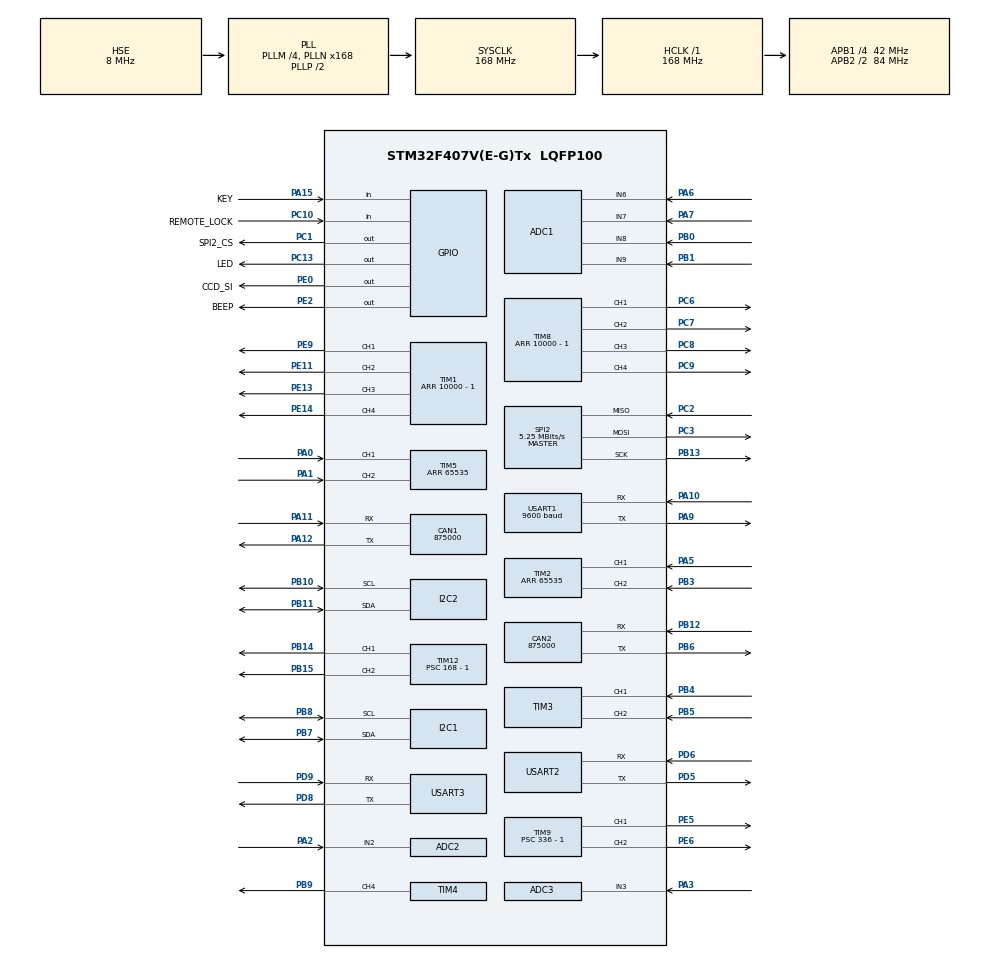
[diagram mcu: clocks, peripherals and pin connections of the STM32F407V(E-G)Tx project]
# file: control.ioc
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ADC1.Channel-1\#ChannelRegularConversion=ADC_CHANNEL_6
ADC1.NbrOfConversionFlag=1
ADC1.Rank-1\#ChannelRegularConversion=1
ADC1.SamplingTime-1\#ChannelRegularConversion=ADC_SAMPLETIME_3CYCLES
ADC1.master=1
ADC2.Channel-1\#ChannelRegularConversion=ADC_CHANNEL_2
ADC2.NbrOfConversionFlag=1
ADC2.Rank-1\#ChannelRegularConversion=1
ADC2.SamplingTime-1\#ChannelRegularConversion=ADC_SAMPLETIME_480CYCLES
ADC3.Channel-3\#ChannelRegularConversion=ADC_CHANNEL_3
ADC3.ExternalTrigConv=ADC_EXTERNALTRIGCONV_T4_CC4
ADC3.NbrOfConversionFlag=1
ADC3.Rank-3\#ChannelRegularConversion=1
ADC3.SamplingTime-3\#ChannelRegularConversion=ADC_SAMPLETIME_3CYCLES
CAN1.CalculateBaudRate=875000
CAN1.CalculateTimeBit=1142
CAN1.CalculateTimeQuantum=380.95238095238096
CAN2.CalculateBaudRate=875000
CAN2.CalculateTimeBit=1142
CAN2.CalculateTimeQuantum=380.95238095238096
Dma.ADC3.0.Direction=DMA_PERIPH_TO_MEMORY
Dma.ADC3.0.FIFOMode=DMA_FIFOMODE_DISABLE
Dma.ADC3.0.Instance=DMA2_Stream0
Dma.ADC3.0.MemDataAlignment=DMA_MDATAALIGN_HALFWORD
Dma.ADC3.0.MemInc=DMA_MINC_ENABLE
Dma.ADC3.0.Mode=DMA_NORMAL
Dma.ADC3.0.PeriphDataAlignment=DMA_PDATAALIGN_HALFWORD
Dma.ADC3.0.PeriphInc=DMA_PINC_DISABLE
Dma.ADC3.0.Priority=DMA_PRIORITY_LOW
Dma.Request0=ADC3
Mcu.Family=STM32F4
Mcu.Name=STM32F407V(E-G)Tx
Mcu.Package=LQFP100
NVIC.DMA2_Stream0_IRQn=true\:0\:0\:true\:false\:true\:false\:true\:true
NVIC.PriorityGroup=NVIC_PRIORITYGROUP_4
NVIC.TIM2_IRQn=true\:0\:0\:false\:false\:true\:true\:true\:true
NVIC.TIM3_IRQn=true\:0\:0\:false\:false\:true\:true\:true\:true
NVIC.TIM4_IRQn=true\:0\:0\:false\:false\:true\:true\:true\:true
NVIC.TIM5_IRQn=true\:0\:0\:false\:false\:true\:true\:true\:true
NVIC.USART1_IRQn=true\:14\:0\:true\:false\:true\:true\:true\:true
PA0-WKUP.GPIO_PuPd=GPIO_PULLUP
PA0-WKUP.Signal=S_TIM5_CH1
PA1.GPIO_PuPd=GPIO_PULLUP
PA1.Signal=S_TIM5_CH2
PA10.Mode=Asynchronous
PA10.Signal=USART1_RX
PA11.Mode=CAN_Activate
PA11.Signal=CAN1_RX
PA12.Mode=CAN_Activate
PA12.Signal=CAN1_TX
PA13.Mode=Serial_Wire
PA13.Signal=SYS_JTMS-SWDIO
PA14.Mode=Serial_Wire
PA14.Signal=SYS_JTCK-SWCLK
PA15.GPIO_Label=KEY
PA15.GPIO_PuPd=GPIO_PULLUP
PA15.Signal=GPIO_Input
PA2.Signal=ADCx_IN2
PA3.Signal=ADCx_IN3
PA5.GPIO_PuPd=GPIO_PULLUP
PA5.Signal=S_TIM2_CH1_ETR
PA6.Signal=ADCx_IN6
PA7.Signal=ADCx_IN7
PA9.Mode=Asynchronous
PA9.Signal=USART1_TX
PB0.Signal=ADCx_IN8
PB1.Signal=ADCx_IN9
PB10.Mode=I2C
PB10.Signal=I2C2_SCL
PB11.Mode=I2C
PB11.Signal=I2C2_SDA
PB12.Mode=CAN_Activate
PB12.Signal=CAN2_RX
PB13.Mode=Full_Duplex_Master
PB13.Signal=SPI2_SCK
PB14.Signal=S_TIM12_CH1
PB15.Signal=S_TIM12_CH2
PB3.GPIO_PuPd=GPIO_PULLUP
PB3.Signal=S_TIM2_CH2
PB4.Signal=S_TIM3_CH1
PB5.Signal=S_TIM3_CH2
PB6.Mode=CAN_Activate
PB6.Signal=CAN2_TX
PB7.Mode=I2C
PB7.Signal=I2C1_SDA
PB8.Mode=I2C
PB8.Signal=I2C1_SCL
PB9.Signal=S_TIM4_CH4
PC1.GPIO_Label=SPI2_CS
PC1.GPIO_PuPd=GPIO_PULLUP
PC1.GPIO_Speed=GPIO_SPEED_FREQ_VERY_HIGH
PC1.PinState=GPIO_PIN_SET
PC1.Signal=GPIO_Output
PC10.GPIO_Label=REMOTE_LOCK
PC10.GPIO_PuPd=GPIO_PULLDOWN
PC10.Signal=GPIO_Input
PC13-ANTI_TAMP.GPIO_Label=LED
PC13-ANTI_TAMP.Signal=GPIO_Output
PC2.Mode=Full_Duplex_Master
PC2.Signal=SPI2_MISO
PC3.Mode=Full_Duplex_Master
PC3.Signal=SPI2_MOSI
PC6.Signal=S_TIM8_CH1
PC7.Signal=S_TIM8_CH2
PC8.Signal=S_TIM8_CH3
PC9.Signal=S_TIM8_CH4
PD5.Mode=Asynchronous
PD5.Signal=USART2_TX
PD6.Mode=Asynchronous
PD6.Signal=USART2_RX
PD8.Mode=Asynchronous
PD8.Signal=USART3_TX
PD9.Mode=Asynchronous
PD9.Signal=USART3_RX
PE0.GPIO_Label=CCD_SI
PE0.GPIO_Speed=GPIO_SPEED_FREQ_VERY_HIGH
PE0.Signal=GPIO_Output
PE11.Signal=S_TIM1_CH2
PE13.Signal=S_TIM1_CH3
PE14.Signal=S_TIM1_CH4
PE2.GPIO_Label=BEEP
PE2.Signal=GPIO_Output
PE5.Signal=S_TIM9_CH1
PE6.Signal=S_TIM9_CH2
PE9.Signal=S_TIM1_CH1
PH0-OSC_IN.Mode=HSE-External-Oscillator
PH0-OSC_IN.Signal=RCC_OSC_IN
PH1-OSC_OUT.Mode=HSE-External-Oscillator
PH1-OSC_OUT.Signal=RCC_OSC_OUT
ProjectManager.HeapSize=0x200
ProjectManager.StackSize=0x400
ProjectManager.TargetToolchain=MDK-ARM V5.32
RCC.48MHZClocksFreq_Value=84000000
RCC.AHBFreq_Value=168000000
RCC.APB1CLKDivider=RCC_HCLK_DIV4
RCC.APB1Freq_Value=42000000
RCC.APB1TimFreq_Value=84000000
RCC.APB2CLKDivider=RCC_HCLK_DIV2
RCC.APB2Freq_Value=84000000
RCC.APB2TimFreq_Value=168000000
RCC.CortexFreq_Value=168000000
RCC.HCLKFreq_Value=168000000
RCC.HSE_VALUE=8000000
RCC.HSI_VALUE=16000000
RCC.LSE_VALUE=32768
RCC.PLLM=4
RCC.PLLN=168
RCC.PLLSourceVirtual=RCC_PLLSOURCE_HSE
RCC.SYSCLKFreq_VALUE=168000000
RCC.SYSCLKSource=RCC_SYSCLKSOURCE_PLLCLK
RCC.VCOOutputFreq_Value=336000000
SH.ADCx_IN2.0=ADC2_IN2,IN2
SH.ADCx_IN3.0=ADC3_IN3,IN3
SH.ADCx_IN6.0=ADC1_IN6,IN6
SH.ADCx_IN7.0=ADC1_IN7,IN7
SH.ADCx_IN8.0=ADC1_IN8,IN8
SH.ADCx_IN9.0=ADC1_IN9,IN9
SH.S_TIM12_CH1.0=TIM12_CH1,PWM Generation1 CH1
SH.S_TIM12_CH2.0=TIM12_CH2,PWM Generation2 CH2
SH.S_TIM1_CH1.0=TIM1_CH1,PWM Generation1 CH1
SH.S_TIM1_CH2.0=TIM1_CH2,PWM Generation2 CH2
SH.S_TIM1_CH3.0=TIM1_CH3,PWM Generation3 CH3
SH.S_TIM1_CH4.0=TIM1_CH4,PWM Generation4 CH4
SH.S_TIM2_CH1_ETR.0=TIM2_CH1,Encoder_Interface
SH.S_TIM2_CH2.0=TIM2_CH2,Encoder_Interface
SH.S_TIM3_CH1.0=TIM3_CH1,Encoder_Interface
SH.S_TIM3_CH2.0=TIM3_CH2,Encoder_Interface
SH.S_TIM4_CH4.0=TIM4_CH4,PWM Generation4 CH4
SH.S_TIM5_CH1.0=TIM5_CH1,Encoder_Interface
SH.S_TIM5_CH2.0=TIM5_CH2,Encoder_Interface
SH.S_TIM8_CH1.0=TIM8_CH1,PWM Generation1 CH1
SH.S_TIM8_CH2.0=TIM8_CH2,PWM Generation2 CH2
SH.S_TIM8_CH3.0=TIM8_CH3,PWM Generation3 CH3
SH.S_TIM8_CH4.0=TIM8_CH4,PWM Generation4 CH4
SH.S_TIM9_CH1.0=TIM9_CH1,PWM Generation1 CH1
SH.S_TIM9_CH2.0=TIM9_CH2,PWM Generation2 CH2
SPI2.BaudRatePrescaler=SPI_BAUDRATEPRESCALER_8
SPI2.CLKPolarity=SPI_POLARITY_HIGH
SPI2.CalculateBaudRate=5.25 MBits/s
SPI2.Direction=SPI_DIRECTION_2LINES
SPI2.Mode=SPI_MODE_MASTER
SPI2.VirtualType=VM_MASTER
TIM1.Channel-PWM\ Generation1\ CH1=TIM_CHANNEL_1
TIM1.Channel-PWM\ Generation2\ CH2=TIM_CHANNEL_2
TIM1.Channel-PWM\ Generation3\ CH3=TIM_CHANNEL_3
TIM1.Channel-PWM\ Generation4\ CH4=TIM_CHANNEL_4
TIM1.OCMode_PWM-PWM\ Generation2\ CH2=TIM_OCMODE_PWM1
TIM1.OCPolarity_2=TIM_OCPOLARITY_HIGH
TIM1.OCPolarity_4=TIM_OCPOLARITY_HIGH
TIM1.Period=10000 - 1
TIM12.Channel-PWM\ Generation1\ CH1=TIM_CHANNEL_1
TIM12.Channel-PWM\ Generation2\ CH2=TIM_CHANNEL_2
TIM12.Period=10000 - 1
TIM12.Prescaler=168 - 1
TIM2.EncoderMode=TIM_ENCODERMODE_TI12
TIM2.Period=65535
TIM3.EncoderMode=TIM_ENCODERMODE_TI12
TIM4.Channel-PWM\ Generation4\ CH4=TIM_CHANNEL_4
TIM4.Period=168*4 - 1
TIM4.Pulse-PWM\ Generation4\ CH4=84*4
TIM4.TIM_MasterOutputTrigger=TIM_TRGO_OC4REF
TIM5.EncoderMode=TIM_ENCODERMODE_TI12
TIM5.Period=65535
TIM8.Channel-PWM\ Generation1\ CH1=TIM_CHANNEL_1
TIM8.Channel-PWM\ Generation2\ CH2=TIM_CHANNEL_2
TIM8.Channel-PWM\ Generation3\ CH3=TIM_CHANNEL_3
TIM8.Channel-PWM\ Generation4\ CH4=TIM_CHANNEL_4
TIM8.OCPolarity_2=TIM_OCPOLARITY_HIGH
TIM8.OCPolarity_4=TIM_OCPOLARITY_HIGH
TIM8.Period=10000 - 1
TIM9.Channel-PWM\ Generation1\ CH1=TIM_CHANNEL_1
TIM9.Channel-PWM\ Generation2\ CH2=TIM_CHANNEL_2
TIM9.Period=10000 - 1
TIM9.Prescaler=336 - 1
USART1.BaudRate=9600
USART1.VirtualMode=VM_ASYNC
USART2.VirtualMode=VM_ASYNC
USART3.VirtualMode=VM_ASYNC
VP_TIM12_VS_ClockSourceINT.Mode=Internal
VP_TIM1_VS_ClockSourceINT.Mode=Internal
VP_TIM4_VS_ClockSourceINT.Mode=Internal
VP_TIM8_VS_ClockSourceINT.Mode=Internal
VP_TIM9_VS_ClockSourceINT.Mode=Internal
board=custom

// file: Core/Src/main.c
/* USER CODE BEGIN Header */
/**
  ******************************************************************************
  * @file           : main.c
  * @brief          : Main program body
  ******************************************************************************
  * @attention
  *
  * Copyright (c) 2024 STMicroelectronics.
  * All rights reserved.
  *
  * This software is licensed under terms that can be found in the LICENSE file
  * in the root directory of this software component.
  * If no LICENSE file comes with this software, it is provided AS-IS.
  *
  ******************************************************************************
  */
/* USER CODE END Header */
#include "main.h"
#include "adc.h"
#include "can.h"
#include "dma.h"
#include "i2c.h"
#include "spi.h"
#include "tim.h"
#include "usart.h"
#include "gpio.h"

/* USER CODE BEGIN Includes */
#include "task.h"
/* USER CODE END Includes */

void SystemClock_Config(void);

int main(void)
{

  /* MCU Configuration--------------------------------------------------------*/

  /* Reset of all peripherals, Initializes the Flash interface and the Systick. */
  HAL_Init();

  /* Configure the system clock */
  SystemClock_Config();

  /* Initialize all configured peripherals */
  MX_GPIO_Init();
  MX_DMA_Init();
  MX_ADC1_Init();
  MX_ADC2_Init();
  MX_ADC3_Init();
  MX_CAN1_Init();
  MX_CAN2_Init();
  MX_I2C1_Init();
  MX_SPI2_Init();
  MX_TIM1_Init();
  MX_TIM2_Init();
  MX_TIM3_Init();
  MX_TIM4_Init();
  MX_TIM5_Init();
  MX_TIM8_Init();
  MX_TIM9_Init();
  MX_TIM12_Init();
  MX_USART1_UART_Init();
  MX_USART2_UART_Init();
  MX_USART3_UART_Init();
  MX_I2C2_Init();
  /* USER CODE BEGIN 2 */
    setup();
    HAL_Delay(1999);
  /* USER CODE END 2 */

  /* Infinite loop */
  while (1)
  {

    /* USER CODE BEGIN 3 */
    loop();
  }
  /* USER CODE END 3 */
}

void SystemClock_Config(void)
{
  RCC_OscInitTypeDef RCC_OscInitStruct = {0};
  RCC_ClkInitTypeDef RCC_ClkInitStruct = {0};

  /** Configure the main internal regulator output voltage
  */
  __HAL_RCC_PWR_CLK_ENABLE();
  __HAL_PWR_VOLTAGESCALING_CONFIG(PWR_REGULATOR_VOLTAGE_SCALE1);

  /** Initializes the RCC Oscillators according to the specified parameters
  * in the RCC_OscInitTypeDef structure.
  */
  RCC_OscInitStruct.OscillatorType = RCC_OSCILLATORTYPE_HSE;
  RCC_OscInitStruct.HSEState = RCC_HSE_ON;
  RCC_OscInitStruct.PLL.PLLState = RCC_PLL_ON;
  RCC_OscInitStruct.PLL.PLLSource = RCC_PLLSOURCE_HSE;
  RCC_OscInitStruct.PLL.PLLM = 4;
  RCC_OscInitStruct.PLL.PLLN = 168;
  RCC_OscInitStruct.PLL.PLLP = RCC_PLLP_DIV2;
  RCC_OscInitStruct.PLL.PLLQ = 4;
  if (HAL_RCC_OscConfig(&RCC_OscInitStruct) != HAL_OK)
  {
    Error_Handler();
  }

  /** Initializes the CPU, AHB and APB buses clocks
  */
  RCC_ClkInitStruct.ClockType = RCC_CLOCKTYPE_HCLK|RCC_CLOCKTYPE_SYSCLK
                              |RCC_CLOCKTYPE_PCLK1|RCC_CLOCKTYPE_PCLK2;
  RCC_ClkInitStruct.SYSCLKSource = RCC_SYSCLKSOURCE_PLLCLK;
  RCC_ClkInitStruct.AHBCLKDivider = RCC_SYSCLK_DIV1;
  RCC_ClkInitStruct.APB1CLKDivider = RCC_HCLK_DIV4;
  RCC_ClkInitStruct.APB2CLKDivider = RCC_HCLK_DIV2;

  if (HAL_RCC_ClockConfig(&RCC_ClkInitStruct, FLASH_LATENCY_5) != HAL_OK)
  {
    Error_Handler();
  }
}

void Error_Handler(void)
{
  __disable_irq();
  while (1)
  {
  }
}
